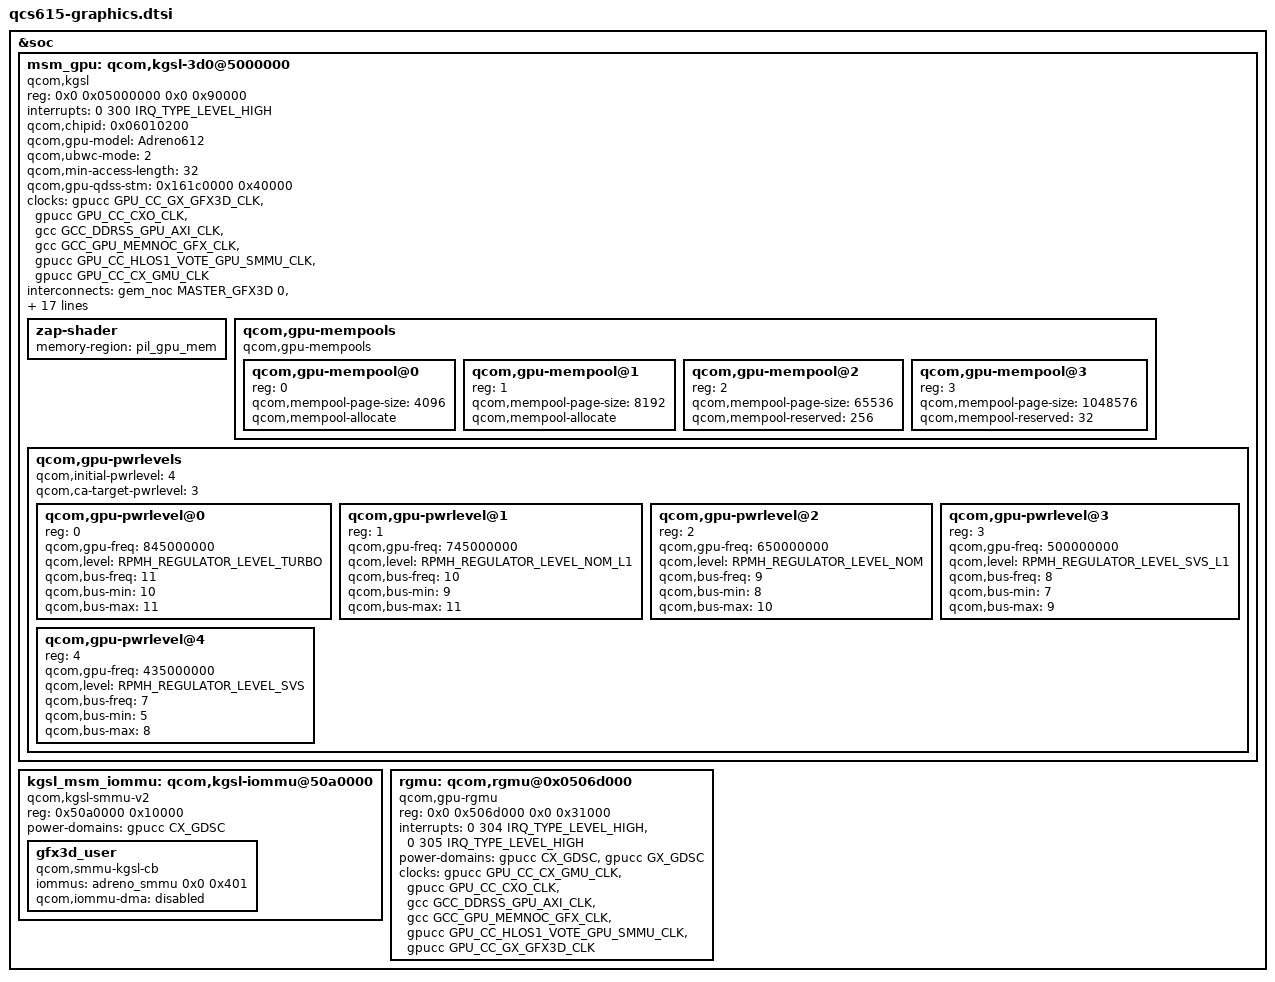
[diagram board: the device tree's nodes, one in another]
/*
 * Copyright (c) Qualcomm Technologies, Inc. and/or its subsidiaries.
 */
// SPDX-License-Identifier: BSD-3-Clause

#define KHZ_TO_KBPS(khz, w) ((khz * 1000 * w) / (1024))

&soc {
	msm_gpu: qcom,kgsl-3d0@5000000 {
		compatible = "qcom,kgsl";
		status = "ok";
		reg = <0x0 0x05000000 0x0 0x90000>;
		reg-names = "kgsl_3d0_reg_memory";
		interrupts = <0 300 IRQ_TYPE_LEVEL_HIGH>;
		interrupt-names = "kgsl_3d0_irq";

		qcom,chipid = <0x06010200>;
		qcom,gpu-model = "Adreno612";

		qcom,ubwc-mode = <2>;
		qcom,min-access-length = <32>;

		/* base addr, size */
		qcom,gpu-qdss-stm = <0x161c0000 0x40000>;
		#cooling-cells = <2>;

		clocks = <&gpucc GPU_CC_GX_GFX3D_CLK>,
			<&gpucc GPU_CC_CXO_CLK>,
			<&gcc GCC_DDRSS_GPU_AXI_CLK>,
			<&gcc GCC_GPU_MEMNOC_GFX_CLK>,
			<&gpucc GPU_CC_HLOS1_VOTE_GPU_SMMU_CLK>,
			<&gpucc GPU_CC_CX_GMU_CLK>;

		clock-names = "core_clk", "rbbmtimer_clk", "gcc_gpu_axi_clk", "gcc_gpu_memnoc_gfx",
				"gpu_cc_hlos1_vote_gpu_smmu", "gmu_clk";

		interconnects = <&gem_noc MASTER_GFX3D 0 &mc_virt SLAVE_EBI1 0>;
		interconnect-names = "gpu_icc_path";

		qcom,bus-table-ddr =
			<KHZ_TO_KBPS(0, 4)>,       /* index=0  */
			<KHZ_TO_KBPS(100000, 4)>,  /* index=1  (Low SVS) */
			<KHZ_TO_KBPS(200000, 4)>,  /* index=2  (Low SVS) */
			<KHZ_TO_KBPS(300000, 4)>,  /* index=3  (Low SVS) */
			<KHZ_TO_KBPS(451200, 4)>,  /* index=4  (Low SVS) */
			<KHZ_TO_KBPS(547200, 4)>,  /* index=5  (Low SVS) */
			<KHZ_TO_KBPS(681600, 4)>,  /* index=6  (SVS)     */
			<KHZ_TO_KBPS(768000, 4)>,  /* index=7  (SVS)     */
			<KHZ_TO_KBPS(1017600, 4)>, /* index=8  (SVS L1)  */
			<KHZ_TO_KBPS(1353600, 4)>, /* index=9  (NOM)     */
			<KHZ_TO_KBPS(1555200, 4)>, /* index=10 (NOM)     */
			<KHZ_TO_KBPS(1804800, 4)>; /* index=11 (TURBO)   */

		qcom,bus-table-cnoc =
			<0>,   /* Off */
			<100>; /* On */

		/* Enable context aware freq. scaling */
		qcom,enable-ca-jump;
		/* Context aware jump busy penalty in us */
		qcom,ca-busy-penalty = <12000>;
		/* Context aware jump target power level */
		qcom,ca-target-pwrlevel = <3>;

		zap-shader {
			memory-region = <&pil_gpu_mem>;
		};

		/* GPU Mempools */
		qcom,gpu-mempools {
			#address-cells = <1>;
			#size-cells = <0>;
			compatible = "qcom,gpu-mempools";

			/* 4K Page Pool configuration */
			qcom,gpu-mempool@0 {
				reg = <0>;
				qcom,mempool-page-size = <4096>;
				qcom,mempool-allocate;
			};
			/* 8K Page Pool configuration */
			qcom,gpu-mempool@1 {
				reg = <1>;
				qcom,mempool-page-size = <8192>;
				qcom,mempool-allocate;
			};
			/* 64K Page Pool configuration */
			qcom,gpu-mempool@2 {
				reg = <2>;
				qcom,mempool-page-size = <65536>;
				qcom,mempool-reserved = <256>;
			};
			/* 1M Page Pool configuration */
			qcom,gpu-mempool@3 {
				reg = <3>;
				qcom,mempool-page-size = <1048576>;
				qcom,mempool-reserved = <32>;
			};
		};

		qcom,gpu-pwrlevels {
			#address-cells = <1>;
			#size-cells = <0>;

			qcom,initial-pwrlevel = <4>;
			qcom,ca-target-pwrlevel = <3>;

			/* TURBO */
			qcom,gpu-pwrlevel@0 {
				reg = <0>;
				qcom,gpu-freq = <845000000>;
				qcom,level = <RPMH_REGULATOR_LEVEL_TURBO>;
				qcom,bus-freq = <11>;
				qcom,bus-min = <10>;
				qcom,bus-max = <11>;
			};

			/* NOM L1 */
			qcom,gpu-pwrlevel@1 {
				reg = <1>;
				qcom,gpu-freq = <745000000>;
				qcom,level = <RPMH_REGULATOR_LEVEL_NOM_L1>;
				qcom,bus-freq = <10>;
				qcom,bus-min = <9>;
				qcom,bus-max = <11>;
			};

			/* NOM */
			qcom,gpu-pwrlevel@2 {
				reg = <2>;
				qcom,gpu-freq = <650000000>;
				qcom,level = <RPMH_REGULATOR_LEVEL_NOM>;
				qcom,bus-freq = <9>;
				qcom,bus-min = <8>;
				qcom,bus-max = <10>;
			};

			/* SVS L1 */
			qcom,gpu-pwrlevel@3 {
				reg = <3>;
				qcom,gpu-freq = <500000000>;
				qcom,level = <RPMH_REGULATOR_LEVEL_SVS_L1>;
				qcom,bus-freq = <8>;
				qcom,bus-min = <7>;
				qcom,bus-max = <9>;
			};

			/* SVS */
			qcom,gpu-pwrlevel@4 {
				reg = <4>;
				qcom,gpu-freq = <435000000>;
				qcom,level = <RPMH_REGULATOR_LEVEL_SVS>;
				qcom,bus-freq = <7>;
				qcom,bus-min = <5>;
				qcom,bus-max = <8>;
			};
		};
	};

	kgsl_msm_iommu: qcom,kgsl-iommu@50a0000 {
		compatible = "qcom,kgsl-smmu-v2";

		reg = <0x50a0000 0x10000>;
		power-domains = <&gpucc CX_GDSC>;

		gfx3d_user: gfx3d_user {
			compatible = "qcom,smmu-kgsl-cb", "qcom,adreno-gmu";
			iommus = <&adreno_smmu 0x0 0x401>;
			qcom,iommu-dma = "disabled";
		};

	};

	rgmu: qcom,rgmu@0x0506d000 {
		compatible = "qcom,gpu-rgmu";

		reg = <0x0 0x506d000 0x0 0x31000>;
		reg-names = "kgsl_rgmu";

		interrupts = <0 304 IRQ_TYPE_LEVEL_HIGH>,
			<0 305 IRQ_TYPE_LEVEL_HIGH>;
		interrupt-names = "kgsl_oob", "kgsl_rgmu";

		power-domains = <&gpucc CX_GDSC>,
				    <&gpucc GX_GDSC>;
		power-domain-names = "cx", "gx";

		clocks = <&gpucc GPU_CC_CX_GMU_CLK>,
			<&gpucc GPU_CC_CXO_CLK>,
			<&gcc GCC_DDRSS_GPU_AXI_CLK>,
			<&gcc GCC_GPU_MEMNOC_GFX_CLK>,
			<&gpucc GPU_CC_HLOS1_VOTE_GPU_SMMU_CLK>,
			<&gpucc GPU_CC_GX_GFX3D_CLK>;

		clock-names = "gmu", "rbbmtimer", "mem",
				"mem_iface", "smmu_vote", "core";
	};
};
